# K1921VK028 register map
Vendor: NIIET; Series: K1921VKx; File version: 2.17
CPU: CM4 r0p1, little endian, MPU, FPU, 4 interrupt priority bits
Registers are 32-bit, read-write, reset 0x0 unless marked. A register's access mark holds for its fields unless they carry their own. Offsets are from the block's base; [hi:lo] are bit positions; lines under a group give offsets from that group; {n}, {i} and the like mark numbered series.

## MFLASH — Mainflash control registers
Base 0x40060000
0x00 ADDR — Address Register
  [20:0] VAL — Address value for flash operations
{0x4+4i} DATA[{i}] (i=0..15) group
  0x00 DATA
    [31:0] VAL — Data register value for flash operations
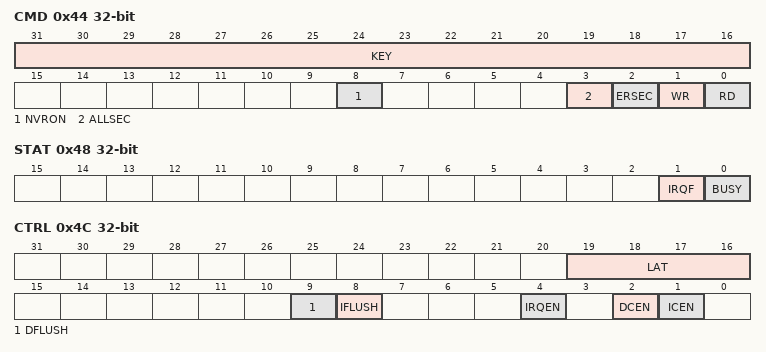
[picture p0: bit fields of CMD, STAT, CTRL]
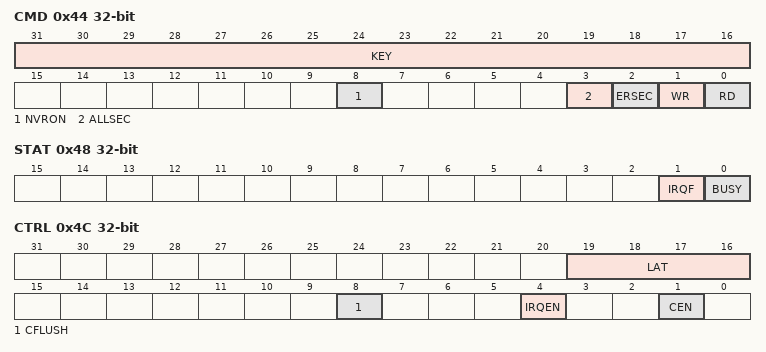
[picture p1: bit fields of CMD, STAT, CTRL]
0x44 CMD — Command Register
  [31:16] KEY — Magic Key for flash access "C0DE"
    0xC0DE=Access (magic Key for flash access)
  [8] NVRON — NVR access bit
  [3] ALLSEC — Select all sectors for erase
  [2] ERSEC — Erase sector enable command
  [1] WR — Write enable command
  [0] RD — Read enable command
0x48 STAT — Status Register
  [1] IRQF — IRQ Flag set when command done. Set by hardware only if IRQEN bit is set.
  [0] BUSY ro — Busy status bit when command is processing
0x4C CTRL — Control Register
  [19:16] LAT
  [9] DFLUSH wo — Flush D-Cache request bit
  [8] IFLUSH wo — Flush I-Cache request bit
  [4] IRQEN — Interrupt enable bit
  [2] DCEN — D-Cache enable bit
  [1] ICEN — I-Cache enable bit
0x50 ICSTAT ro — I-CACHE Status Register
  [0] BUSY — I-Cache busy
0x54 DCSTAT ro — D-CACHE Status Register
  [0] BUSY — D-Cache busy

## BFLASH — Bootflash control registers
Base 0x40061000
0x00 ADDR — Address Register
  [18:0] VAL — Address value for flash operations
{0x4+4i} DATA[{i}] (i=0..3) group
  0x00 DATA
    [31:0] VAL — Data register value for flash operations
0x44 CMD — Command Register
  [31:16] KEY — Magic Key for flash access "C0DE"
    0xC0DE=Access (magic Key for flash access)
  [8] NVRON — INFO access bit
  [3] ALLSEC — Enable Erase all flash memory
  [2] ERSEC — Erase sector enable command
  [1] WR — Write enable command
  [0] RD — Read enable command
0x48 STAT — Status Register
  [1] IRQF — IRQ Flag set when command done. Set by hardware only if IRQEN bit is set.
  [0] BUSY ro — Busy status bit when command is processing
0x4C CTRL — Control Register
  [19:16] LAT — Flash latency
  [8] CFLUSH wo — Cache bit
  [4] IRQEN — Interrupt enable bit
  [1] CEN — Cache enable bit

## EXTMEM — External memory control registers
Base 0x40062000
{0x0+4i} WINCFG[{i}] (i=0..7) group
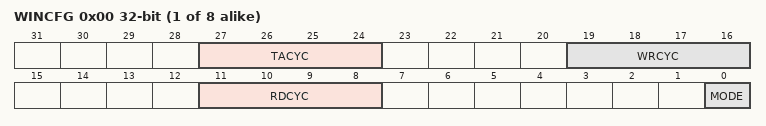
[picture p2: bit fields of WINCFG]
  0x00 WINCFG — Window Configuration
    [27:24] TACYC — Turnaround cycles
    [19:16] WRCYC — Additional Write cycles
    [11:8] RDCYC — Additional Read cycles
    [0] MODE — 8/16 bit mode. When 1 - 16 bit mode enabled
      0=8 bit mode; 1=16 bit mode

## SPI0 — SPI control registers
Base 0x4008D000
Same registers: SPI1 0x4008E000, SPI2 0x4008F000, SPI3 0x40090000
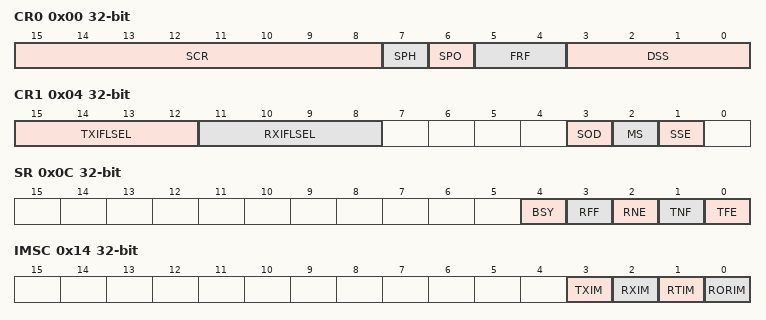
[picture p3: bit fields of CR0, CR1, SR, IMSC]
0x00 CR0 — Control register 0
  [15:8] SCR
  [7] SPH — Phase SSPCLKOUT
  [6] SPO — Polarity SSPCLKOUT
  [5:4] FRF
    0=SPI (SPI of Motorola); 1=SSI (SSI of Texas Instruments); 2=Microwire of National Semiconductor
  [3:0] DSS
    {v}={v+1}bit (data size {v+1} bit) (v=3..15)
0x04 CR1 — Control register 1
  [15:12] TXIFLSEL
  [11:8] RXIFLSEL
  [3] SOD — Disable bit data
  [2] MS — Select mode
  [1] SSE — Enable transceiver
0x08 DR — Data register
  [15:0] DATA
0x0C SR ro — State register
  [4] BSY — Activity flag
  [3] RFF — Indicate full receive buffer
  [2] RNE — Indicate not empty receive buffer
  [1] TNF — Indicator the transmitter FIFO buffer is not full
  [0] TFE — FIFO buffer empty flag transmitter
0x10 CPSR — Clock division factor register
  [7:0] CPSDVSR ro
0x14 IMSC — Mask interrupt register
  [3] TXIM — SSPTXINTR interrupt mask bit to fill 50% or less of the FIFO buffer of the transmitter
  [2] RXIM — SSPRXINTR interrupt mask bit to fill 50% or less of the receiver FIFO buffer
  [1] RTIM — Interrupt mask bit SSPRTINTR timeout receiver
  [0] RORIM — Interrupt mask bit SSPRORINTR buffer overflow receiver
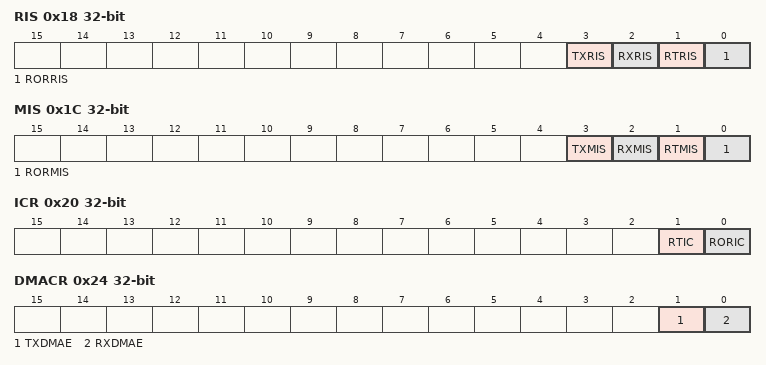
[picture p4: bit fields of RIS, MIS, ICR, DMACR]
0x18 RIS ro — Status register interrupt without mask
  [3] TXRIS — Interrupt status before masking SSPTXINTR
  [2] RXRIS — Interrupt status before masking SSPRXINTR
  [1] RTRIS — Interrupt status before masking SSPRTINTR
  [0] RORRIS — Interrupt status before masking SSPRORINTR
0x1C MIS ro — Status register interrupt masking account
  [3] TXMIS — Masked interrupt status SSPTXINTR
  [2] RXMIS — Masked interrupt status SSPRXINTR
  [1] RTMIS — Masked interrupt status SSPRTINTR
  [0] RORMIS — Masked interrupt status SSPRORINTR
0x20 ICR wo — Register reset interrupt
  [1] RTIC — Reset interrupt SSPRTINTR
  [0] RORIC — Reset interrupt SSPRORINTR
0x24 DMACR — Control register DMA
  [1] TXDMAE — DMA enable bit transmission
  [0] RXDMAE — DMA enable bit at reception
